AUTOSAR XML (schema 4-0-3)
standard types defined: uint8, Boolean, UInt16, UInt32, UInt8
package /AUTOSAR_Platform/DataConstrs
  range DC_Boolean: raw 0..1
  range DC_UInt16: raw 0..65535
  range DC_UInt8: raw 0..255
package /PATAC/Facility/DataTypes/Implementation
  compu method COMPU_Boolean: 0=FALSE, 1=TRUE
  unit NoUnit: factor-si-to-unit=1, offset-si-to-unit=0
package /PATAC/MSM/ComponentTypes
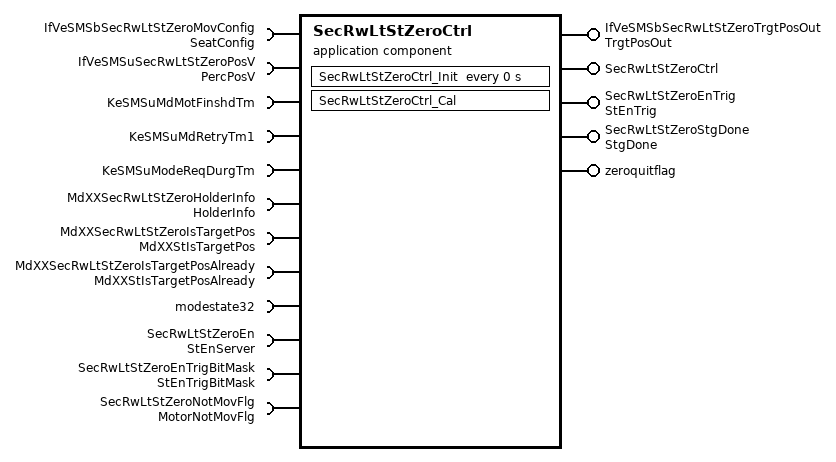
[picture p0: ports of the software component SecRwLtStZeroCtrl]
  application sw component type SecRwLtStZeroCtrl
    5 x provide port:
      IfVeSMSbSecRwLtStZeroTrgtPosOut: nonqueued-sender-com-spec{data-element=TrgtPosOut/Val, init-value=0}, provided-interface=TrgtPosOut
      SecRwLtStZeroCtrl: server-com-spec{operation=Cal, queue-length=1}, provided-interface=SecRwLtStZeroCtrl
      SecRwLtStZeroEnTrig: nonqueued-sender-com-spec{data-element=StEnTrig/Val, init-value=0}, provided-interface=StEnTrig
      SecRwLtStZeroStgDone: nonqueued-sender-com-spec{data-element=StgDone/Val, init-value=0}, provided-interface=StgDone
      zeroquitflag: nonqueued-sender-com-spec{data-element=zeroquitflag/Val, init-value=0}, provided-interface=zeroquitflag
    12 x require port:
      IfVeSMSbSecRwLtStZeroMovConfig: nonqueued-receiver-com-spec{data-element=SeatConfig/Val, filter=data-filter-type=ALWAYS, init-value=0}, required-interface=SeatConfig
      IfVeSMSuSecRwLtStZeroPosV: nonqueued-receiver-com-spec{data-element=PercPosV/Val, filter=data-filter-type=ALWAYS, init-value=0}, required-interface=PercPosV
      KeSMSuMdMotFinshdTm: parameter-require-com-spec{init-value=0, parameter=KeSMSuMdMotFinshdTm/Val}, required-interface=KeSMSuMdMotFinshdTm
      KeSMSuMdRetryTm1: parameter-require-com-spec{init-value=0, parameter=KeSMSuMdRetryTm1/Val}, required-interface=KeSMSuMdRetryTm1
      KeSMSuModeReqDurgTm: parameter-require-com-spec{init-value=0, parameter=KeSMSuModeReqDurgTm/Val}, required-interface=KeSMSuModeReqDurgTm
      MdXXSecRwLtStZeroHolderInfo: nonqueued-receiver-com-spec{data-element=HolderInfo/Val, filter=data-filter-type=ALWAYS, init-value=0}, required-interface=HolderInfo
      MdXXSecRwLtStZeroIsTargetPos: nonqueued-receiver-com-spec{data-element=MdXXStIsTargetPos/Val, filter=data-filter-type=ALWAYS, init-value=0}, required-interface=MdXXStIsTargetPos
      MdXXSecRwLtStZeroIsTargetPosAlready: nonqueued-receiver-com-spec{data-element=MdXXStIsTargetPosAlready/Val, filter=data-filter-type=ALWAYS, init-value=0}, required-interface=MdXXStIsTargetPosAlready
      modestate32: nonqueued-receiver-com-spec{data-element=modestate32/Val, filter=data-filter-type=ALWAYS, init-value=0}, required-interface=modestate32
      SecRwLtStZeroEn: required-com-specs=[Clear, Get, Set], required-interface=StEnServer
      SecRwLtStZeroEnTrigBitMask: nonqueued-receiver-com-spec{data-element=StEnTrigBitMask/Val, filter=data-filter-type=ALWAYS, init-value=0}, required-interface=StEnTrigBitMask
      SecRwLtStZeroNotMovFlg: nonqueued-receiver-com-spec{data-element=MotorNotMovFlg/Val, filter=data-filter-type=ALWAYS, init-value=0}, required-interface=MotorNotMovFlg
    behavior SecRwLtStZeroCtrl_InternalBehavior
      operation invoked event OIT_SecRwLtStZeroCtrl_Cal_SecRwLtStZeroCtrl_Cal: start-on-event=SecRwLtStZeroCtrl_Cal, operation=SecRwLtStZeroCtrl.Cal
      timing event SecRwLtStZeroCtrl_InitEvent: start-on-event=SecRwLtStZeroCtrl_Init, period=0
      runnable SecRwLtStZeroCtrl_Cal
        data-receive-point-by-arguments:
          8 x access:
            REC_IfVeSMSbSecRwLtStZeroMovConfig_Val: accessed-variable=IfVeSMSbSecRwLtStZeroMovConfig.Val
            REC_IfVeSMSuSecRwLtStZeroPosV_Val: accessed-variable=IfVeSMSuSecRwLtStZeroPosV.Val
            REC_MdXXSecRwLtStZeroHolderInfo_Val: accessed-variable=MdXXSecRwLtStZeroHolderInfo.Val
            REC_MdXXSecRwLtStZeroIsTargetPos_Val: accessed-variable=MdXXSecRwLtStZeroIsTargetPos.Val
            REC_MdXXSecRwLtStZeroIsTargetPosAlready_Val: accessed-variable=MdXXSecRwLtStZeroIsTargetPosAlready.Val
            REC_modestate32_Val: accessed-variable=modestate32.Val
            REC_SecRwLtStZeroEnTrigBitMask_Val: accessed-variable=SecRwLtStZeroEnTrigBitMask.Val
            REC_SecRwLtStZeroNotMovFlg_Val: accessed-variable=SecRwLtStZeroNotMovFlg.Val
        data-send-points:
          4 x access:
            SEND_IfVeSMSbSecRwLtStZeroTrgtPosOut_Val: accessed-variable=IfVeSMSbSecRwLtStZeroTrgtPosOut.Val
            SEND_SecRwLtStZeroEnTrig_Val: accessed-variable=SecRwLtStZeroEnTrig.Val
            SEND_SecRwLtStZeroStgDone_Val: accessed-variable=SecRwLtStZeroStgDone.Val
            SEND_zeroquitflag_Val: accessed-variable=zeroquitflag.Val
        parameter access PA_KeSMSuMdMotFinshdTm_Val: accessed-parameter=KeSMSuMdMotFinshdTm.Val
        parameter access PA_KeSMSuMdRetryTm1_Val: accessed-parameter=KeSMSuMdRetryTm1.Val
        parameter access PA_KeSMSuModeReqDurgTm_Val: accessed-parameter=KeSMSuModeReqDurgTm.Val
        sync call SC_SecRwLtStZeroEn_Get: operation=SecRwLtStZeroEn.Get, timeout=0
      runnable SecRwLtStZeroCtrl_Init
        parameter access PA_KeSMSuMdMotFinshdTm_Val: accessed-parameter=KeSMSuMdMotFinshdTm.Val
        parameter access PA_KeSMSuMdRetryTm1_Val: accessed-parameter=KeSMSuMdRetryTm1.Val
        parameter access PA_KeSMSuModeReqDurgTm_Val: accessed-parameter=KeSMSuModeReqDurgTm.Val
  swc implementation SecRwLtStZeroCtrl_Implementation: behavior=SecRwLtStZeroCtrl_InternalBehavior
    code-descriptors:
      code Default: artifact-descriptors=autosar-engineering-object={short-label=Default, category=SWSRC}
package /PATAC/MSM/ModeAdjust/CalPortInterface
  parameter interface KeSMSuMdMotFinshdTm
    parameter data prototype Val: sw-calibration-access=READ-WRITE, type=UInt16
  parameter interface KeSMSuModeReqDurgTm
    parameter data prototype Val: sw-calibration-access=READ-WRITE, type=UInt16
package /PATAC/MSM/ModeAdjust/PortInterface
  client server interface SecRwLtStZeroCtrl
    operation Cal
  client server interface StEnServer
    operation Clear
      arg data: type=UInt8, direction=IN, server-argument-impl-policy=USE-ARGUMENT-TYPE
    operation Get
      arg data: type=UInt32, direction=OUT, server-argument-impl-policy=USE-ARGUMENT-TYPE
    operation Set
      arg data: type=UInt8, direction=IN, server-argument-impl-policy=USE-ARGUMENT-TYPE
  11 x sender receiver interface:
    HolderInfo: invalidation-policy{data-element=HolderInfo/Val, handle-invalid=DONT-INVALIDATE}
      data Val: type=UInt32
    MdXXStIsTargetPos: invalidation-policy{data-element=MdXXStIsTargetPos/Val, handle-invalid=DONT-INVALIDATE}
      data Val: type=UInt32
    MdXXStIsTargetPosAlready: invalidation-policy{data-element=MdXXStIsTargetPosAlready/Val, handle-invalid=DONT-INVALIDATE}
      data Val: type=UInt32
    modestate32: invalidation-policy{data-element=modestate32/Val, handle-invalid=DONT-INVALIDATE}
      data Val: type=UInt32
    MotorNotMovFlg: invalidation-policy{data-element=MotorNotMovFlg/Val, handle-invalid=DONT-INVALIDATE}
      data Val: type=Boolean
    PercPosV: invalidation-policy{data-element=PercPosV/Val, handle-invalid=DONT-INVALIDATE}
      data Val: type=Boolean
    StEnTrig: invalidation-policy{data-element=StEnTrig/Val, handle-invalid=DONT-INVALIDATE}
      data Val: type=Boolean
    StEnTrigBitMask: invalidation-policy{data-element=StEnTrigBitMask/Val, handle-invalid=DONT-INVALIDATE}
      data Val: type=UInt32
    StgDone: invalidation-policy{data-element=StgDone/Val, handle-invalid=DONT-INVALIDATE}
      data Val: type=Boolean
    TrgtPosOut: invalidation-policy{data-element=TrgtPosOut/Val, handle-invalid=DONT-INVALIDATE}
      data Val: type=Boolean
    zeroquitflag: invalidation-policy{data-element=zeroquitflag/Val, handle-invalid=DONT-INVALIDATE}
      data Val: type=Boolean
package /PATAC/MSM/PortInterfaces
  parameter interface KeSMSuMdRetryTm1
    parameter data prototype Val: sw-calibration-access=READ-WRITE, type=UInt8
  sender receiver interface SeatConfig: invalidation-policy{data-element=SeatConfig/Val, handle-invalid=DONT-INVALIDATE}
    data Val: type=Boolean
